# PIC32MX254F128D device description
Architecture: MIPS; Family: PIC32MX; Series: PIC32MX
Registers are 32-bit, read-write, no defined reset value unless marked. A register's access mark holds for its fields unless they carry their own. Offsets are from the block's base; [hi:lo] are bit positions; lines under a group give offsets from that group; {n}, {i} and the like mark numbered series.

## INT
Instances: INT 0x1f881000 in periph2
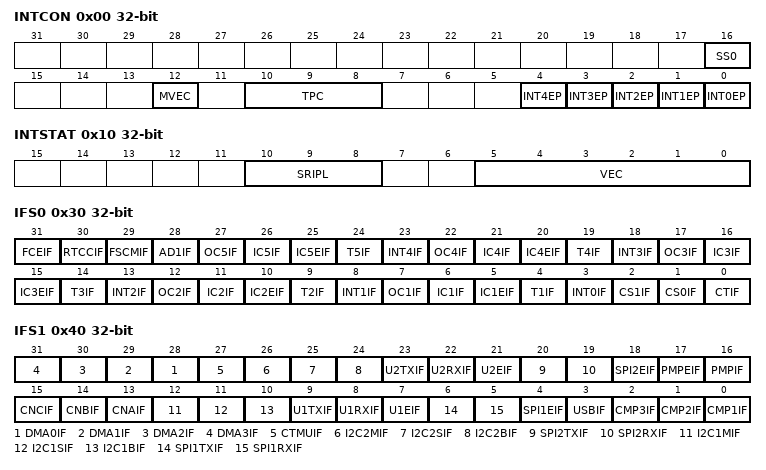
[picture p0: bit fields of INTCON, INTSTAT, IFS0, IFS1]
0x00 INTCON — Interrupt Control Register
  [16] SS0
  [12] MVEC — Multi Vector Configuration bit
    1=Interrupt controller configured for Multi-vectored mode; 0=Interrupt controller configured for Single-vectored mode
  [10:8] TPC — Interrupt Proximity Timer Control bits
    {v}=Interrupts of group priority {v} or lower start the Interrupt Proximity timer (v=2..7); 1=Interrupts of group priority 1 start the Interrupt Proximity timer; 0=Disables Interrupt Proximity timer
  [n] INT{n}EP (n=0..4) — External Interrupt {n} Edge
    1=Rising edge; 0=Falling edge
0x10 INTSTAT — Interrupt Status Register
  [10:8] SRIPL, [5:0] VEC
0x20 IPTMR — Interrupt Proximity Timer Register
0x30 IFS0 — Interrupt Flag Status Register
  [31] FCEIF, [30] RTCCIF, [29] FSCMIF, [28] AD1IF, [5n+2] OC{n}IF (n=1..5), [5n+1] IC{n}IF (n=1..5), [5n] IC{n}EIF (n=1..5), [5n-1] T{n}IF (n=1..5), [5n+3] INT{n}IF (n=0..4), [2] CS1IF, [1] CS0IF, [0] CTIF
0x40 IFS1 — Interrupt Flag Status Register
  [n+28] DMA{n}IF (n=0..3), [27] CTMUIF, [26] I2C2MIF, [25] I2C2SIF, [24] I2C2BIF, [23] U2TXIF, [22] U2RXIF, [21] U2EIF, [20] SPI2TXIF, [19] SPI2RXIF, [18] SPI2EIF, [17] PMPEIF, [16] PMPIF, [15] CNCIF, [14] CNBIF, [13] CNAIF, [12] I2C1MIF, [11] I2C1SIF, [10] I2C1BIF, [9] U1TXIF, [8] U1RXIF, [7] U1EIF, [6] SPI1TXIF, [5] SPI1RXIF, [4] SPI1EIF, [3] USBIF, [2] CMP3IF, [1] CMP2IF, [0] CMP1IF
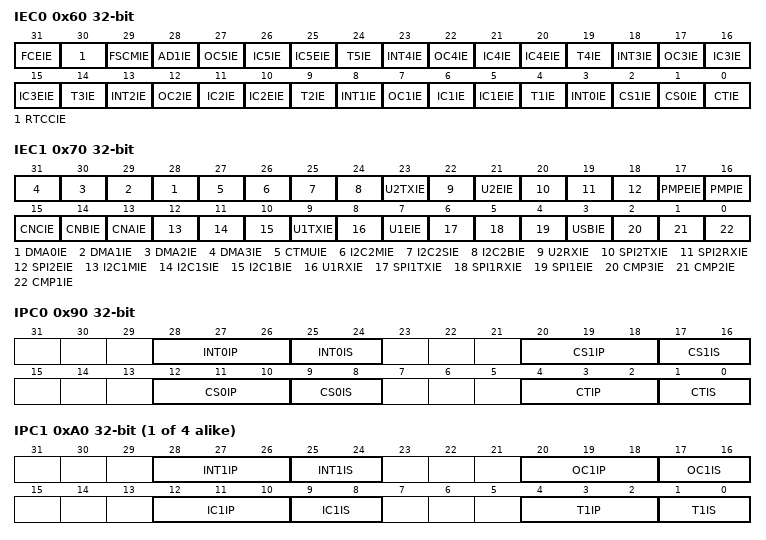
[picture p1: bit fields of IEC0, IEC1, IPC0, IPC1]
0x60 IEC0 — Interrupt Enable Control Register
  [31] FCEIE, [30] RTCCIE, [29] FSCMIE, [28] AD1IE, [5n+2] OC{n}IE (n=1..5), [5n+1] IC{n}IE (n=1..5), [5n] IC{n}EIE (n=1..5), [5n-1] T{n}IE (n=1..5), [5n+3] INT{n}IE (n=0..4), [2] CS1IE, [1] CS0IE, [0] CTIE
0x70 IEC1 — Interrupt Enable Control Register
  [n+28] DMA{n}IE (n=0..3), [27] CTMUIE, [26] I2C2MIE, [25] I2C2SIE, [24] I2C2BIE, [23] U2TXIE, [22] U2RXIE, [21] U2EIE, [20] SPI2TXIE, [19] SPI2RXIE, [18] SPI2EIE, [17] PMPEIE, [16] PMPIE, [15] CNCIE, [14] CNBIE, [13] CNAIE, [12] I2C1MIE, [11] I2C1SIE, [10] I2C1BIE, [9] U1TXIE, [8] U1RXIE, [7] U1EIE, [6] SPI1TXIE, [5] SPI1RXIE, [4] SPI1EIE, [3] USBIE, [2] CMP3IE, [1] CMP2IE, [0] CMP1IE
0x90 IPC0 — Interrupt Priority Control Register
  [28:26] INT0IP, [25:24] INT0IS, [20:18] CS1IP, [17:16] CS1IS, [12:10] CS0IP, [9:8] CS0IS, [4:2] CTIP, [1:0] CTIS
{0x90+0x10*i} IPC{i} (i=1..4) — Interrupt Priority Control Register
  [28:26] INT{i}IP, [25:24] INT{i}IS, [20:18] OC{i}IP, [17:16] OC{i}IS, [12:10] IC{i}IP, [9:8] IC{i}IS, [4:2] T{i}IP, [1:0] T{i}IS
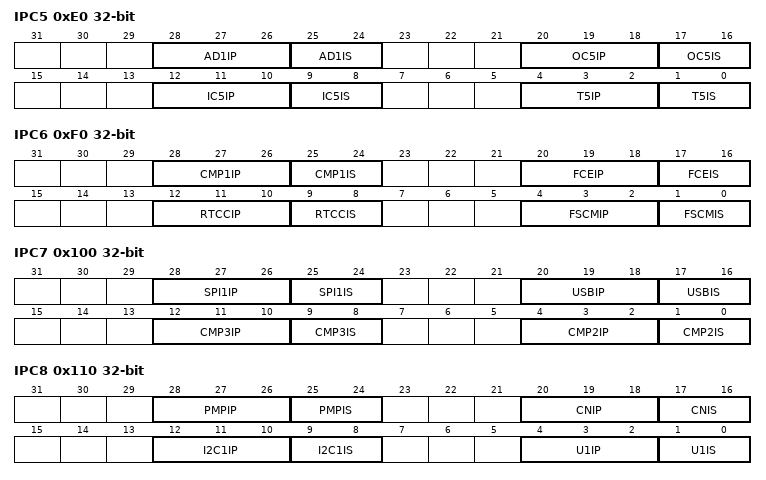
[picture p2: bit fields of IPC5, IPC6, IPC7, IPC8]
0xE0 IPC5 — Interrupt Priority Control Register
  [28:26] AD1IP, [25:24] AD1IS, [20:18] OC5IP, [17:16] OC5IS, [12:10] IC5IP, [9:8] IC5IS, [4:2] T5IP, [1:0] T5IS
0xF0 IPC6 — Interrupt Priority Control Register
  [28:26] CMP1IP, [25:24] CMP1IS, [20:18] FCEIP, [17:16] FCEIS, [12:10] RTCCIP, [9:8] RTCCIS, [4:2] FSCMIP, [1:0] FSCMIS
0x100 IPC7 — Interrupt Priority Control Register
  [28:26] SPI1IP, [25:24] SPI1IS, [20:18] USBIP, [17:16] USBIS, [12:10] CMP3IP, [9:8] CMP3IS, [4:2] CMP2IP, [1:0] CMP2IS
0x110 IPC8 — Interrupt Priority Control Register
  [28:26] PMPIP, [25:24] PMPIS, [20:18] CNIP, [17:16] CNIS, [12:10] I2C1IP, [9:8] I2C1IS, [4:2] U1IP, [1:0] U1IS
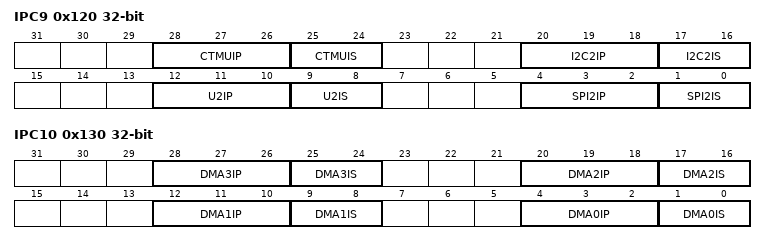
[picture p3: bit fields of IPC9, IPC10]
0x120 IPC9 — Interrupt Priority Control Register
  [28:26] CTMUIP, [25:24] CTMUIS, [20:18] I2C2IP, [17:16] I2C2IS, [12:10] U2IP, [9:8] U2IS, [4:2] SPI2IP, [1:0] SPI2IS
0x130 IPC10 — Interrupt Priority Control Register
  [8n+4:8n+2] DMA{n}IP (n=0..3), [8n+1:8n] DMA{n}IS (n=0..3)

## NVM
Instances: NVM 0x1f80f400 in periph1
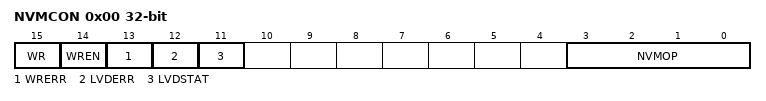
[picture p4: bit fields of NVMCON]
0x00 NVMCON — Programming Control Register
  [15] WR — Write Control bit
    1=Initiate a Flash operation. Hardware clears this bit when the operation completes; 0=Flash operation is complete or inactive
  [14] WREN — Write Enable bit
    1=Enable writes to WR bit and enables HLVD circuit; 0=Disable writes to WR bit and disables HLVD circuit
  [13] WRERR — Write Error bit (LVD circuit must be enabled)
    1=Program or erase sequence did not complete successfully; 0=Program or erase sequence completed normally
  [12] LVDERR — Low-Voltage Detect Error bit (LVD circuit must be enabled)
    1=Low-voltage detected (possible data corruption; 0=Voltage level is acceptable for programming
  [11] LVDSTAT — Low-Voltage Detect Status bit (LVD circuit must be enabled)
    1=Low-voltage event is active; 0=Low-voltage event is not active
  [3:0] NVMOP — NVM Operation bits
    6=No operation; 5=Program Flash Memory (PFM) erase operation: erases PFM; 4=Page erase operation: erases page selected by NVMADDR; 3=Row program operation: programs row selected by NVMADDR; 2=No operation; 1=Word program operation: programs word selected by NVMADDR; 0=No operation
0x10 NVMKEY wo — Programming Unlock Register
0x20 NVMADDR — Flash Address Register
0x30 NVMDATA — Flash Program Data Register
0x40 NVMSRCADDR — Source Data Address Register

## Notices in the file
Copyright (c) 2019 Microchip Technology Inc.
SPDX-License-Identifier: Apache-2.0
Licensed under the Apache License, Version 2.0 (the "License");
you may not use this file except in compliance with the License.
You may obtain a copy of the License at
http://www.apache.org/licenses/LICENSE-2.0
Unless required by applicable law or agreed to in writing, software
distributed under the License is distributed on an "AS IS" BASIS,
WITHOUT WARRANTIES OR CONDITIONS OF ANY KIND, either express or implied.
See the License for the specific language governing permissions and
limitations under the License.
